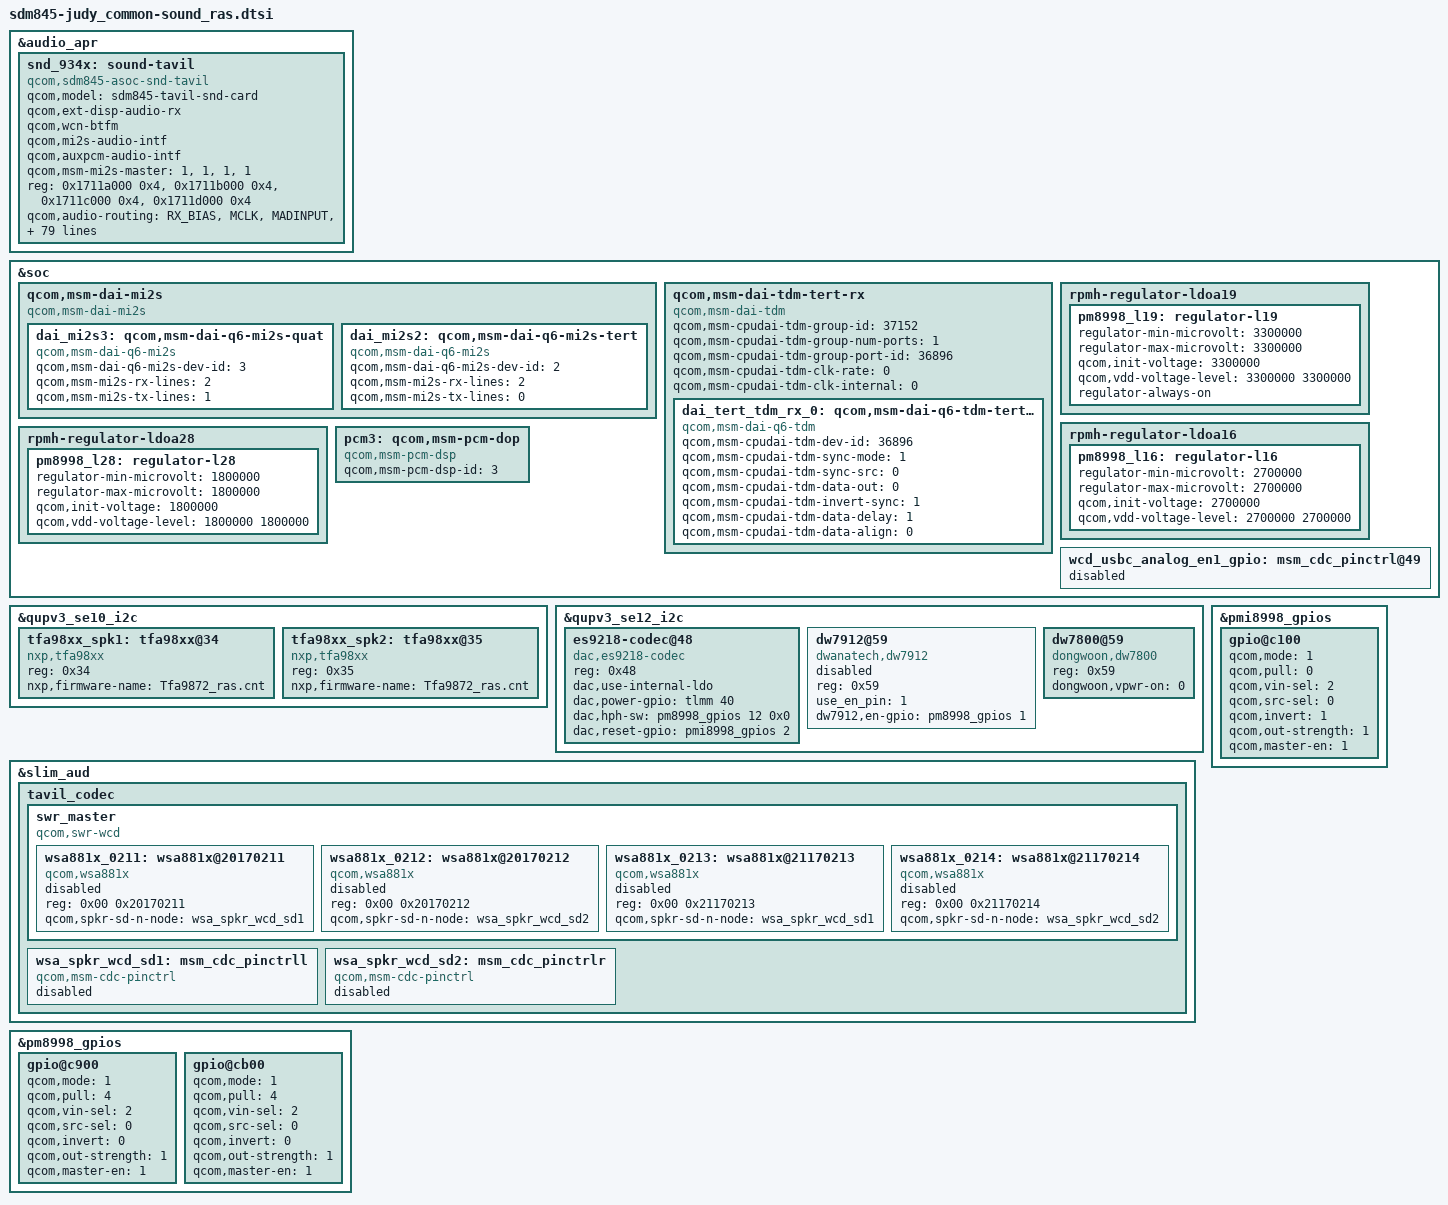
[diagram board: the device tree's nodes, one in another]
/* Copyright (c) 2017, The Linux Foundation. All rights reserved.
 *
 * This program is free software; you can redistribute it and/or modify
 * it under the terms of the GNU General Public License version 2 and
 * only version 2 as published by the Free Software Foundation.
 *
 * This program is distributed in the hope that it will be useful,
 * but WITHOUT ANY WARRANTY; without even the implied warranty of
 * MERCHANTABILITY or FITNESS FOR A PARTICULAR PURPOSE.  See the
 * GNU General Public License for more details.
 */

#include "sdm845-judy_common-sound_overlay.dtsi"
/*
&qupv3_se12_i2c {
	status = "ok";
};
*/
&audio_apr {
	snd_934x: sound-tavil {
		compatible = "qcom,sdm845-asoc-snd-tavil";
		qcom,model = "sdm845-tavil-snd-card";
		qcom,ext-disp-audio-rx;
		qcom,wcn-btfm;
		qcom,mi2s-audio-intf;
		qcom,auxpcm-audio-intf;
		qcom,msm-mi2s-master = <1>, <1>, <1>, <1>;

		reg = <0x1711a000 0x4>,
		      <0x1711b000 0x4>,
		      <0x1711c000 0x4>,
		      <0x1711d000 0x4>;
		reg-names = "lpaif_pri_mode_muxsel",
			    "lpaif_sec_mode_muxsel",
			    "lpaif_tert_mode_muxsel",
			    "lpaif_quat_mode_muxsel";

		qcom,audio-routing =
			"RX_BIAS", "MCLK",
			"MADINPUT", "MCLK",
			"AMIC1", "MIC BIAS1",
			"MIC BIAS1", "Handset Mic",
			"AMIC2", "MIC BIAS2",
			"MIC BIAS2", "Headset Mic",
			"AMIC3", "MIC BIAS3",
			"MIC BIAS3", "Handset 2nd Mic",
			"AMIC4", "MIC BIAS4",
			"MIC BIAS4", "Handset 3rd Mic",
			"DMIC0", "MIC BIAS1",
			"MIC BIAS1", "Digital Mic0";

		qcom,msm-mbhc-hphl-swh = <1>;
		qcom,msm-mbhc-gnd-swh = <0>;
		qcom,msm-mbhc-moist-cfg = <0>, <0>, <1>;
		/delete-property/ qcom,us-euro-gpios;
		qcom,tavil-mclk-clk-freq = <9600000>;
		asoc-platform = <&pcm0>, <&pcm1>, <&pcm2>, <&pcm3>,<&voip>, <&voice>,
				<&loopback>, <&compress>, <&hostless>,
				<&afe>, <&lsm>, <&routing>, <&compr>,
				<&pcm_noirq>;
		asoc-platform-names = "msm-pcm-dsp.0", "msm-pcm-dsp.1",
				"msm-pcm-dsp.2","msm-pcm-dsp.3","msm-voip-dsp",
				"msm-pcm-voice", "msm-pcm-loopback",
				"msm-compress-dsp", "msm-pcm-hostless",
				"msm-pcm-afe", "msm-lsm-client",
				"msm-pcm-routing", "msm-compr-dsp",
				"msm-pcm-dsp-noirq";
		asoc-cpu = <&dai_hdmi>, <&dai_dp>,
				<&dai_mi2s0>, <&dai_mi2s1>,
				<&dai_mi2s2>, <&dai_mi2s3>,
				<&dai_pri_auxpcm>, <&dai_sec_auxpcm>,
				<&dai_tert_auxpcm>, <&dai_quat_auxpcm>,
				<&sb_0_rx>, <&sb_0_tx>, <&sb_1_rx>, <&sb_1_tx>,
				<&sb_2_rx>, <&sb_2_tx>, <&sb_3_rx>, <&sb_3_tx>,
				<&sb_4_rx>, <&sb_4_tx>, <&sb_5_tx>,
				<&afe_pcm_rx>, <&afe_pcm_tx>, <&afe_proxy_rx>,
				<&afe_proxy_tx>, <&incall_record_rx>,
				<&incall_record_tx>, <&incall_music_rx>,
				<&incall_music_2_rx>, <&sb_5_rx>, <&sb_6_rx>,
				<&sb_7_rx>, <&sb_7_tx>, <&sb_8_tx>,
				<&usb_audio_rx>, <&usb_audio_tx>,
				<&dai_pri_tdm_rx_0>, <&dai_pri_tdm_tx_0>,
				<&dai_sec_tdm_rx_0>, <&dai_sec_tdm_tx_0>,
				<&dai_tert_tdm_rx_0>, <&dai_tert_tdm_tx_0>,
				<&dai_quat_tdm_rx_0>, <&dai_quat_tdm_tx_0>;
		asoc-cpu-names = "msm-dai-q6-hdmi.8",  "msm-dai-q6-dp.24608",
				"msm-dai-q6-mi2s.0", "msm-dai-q6-mi2s.1",
				"msm-dai-q6-mi2s.2", "msm-dai-q6-mi2s.3",
				"msm-dai-q6-auxpcm.1", "msm-dai-q6-auxpcm.2",
				"msm-dai-q6-auxpcm.3", "msm-dai-q6-auxpcm.4",
				"msm-dai-q6-dev.16384", "msm-dai-q6-dev.16385",
				"msm-dai-q6-dev.16386", "msm-dai-q6-dev.16387",
				"msm-dai-q6-dev.16388", "msm-dai-q6-dev.16389",
				"msm-dai-q6-dev.16390", "msm-dai-q6-dev.16391",
				"msm-dai-q6-dev.16392", "msm-dai-q6-dev.16393",
				"msm-dai-q6-dev.16395", "msm-dai-q6-dev.224",
				"msm-dai-q6-dev.225", "msm-dai-q6-dev.241",
				"msm-dai-q6-dev.240", "msm-dai-q6-dev.32771",
				"msm-dai-q6-dev.32772", "msm-dai-q6-dev.32773",
				"msm-dai-q6-dev.32770", "msm-dai-q6-dev.16394",
				"msm-dai-q6-dev.16396", "msm-dai-q6-dev.16398",
				"msm-dai-q6-dev.16399", "msm-dai-q6-dev.16401",
				"msm-dai-q6-dev.28672", "msm-dai-q6-dev.28673",
				"msm-dai-q6-tdm.36864", "msm-dai-q6-tdm.36865",
				"msm-dai-q6-tdm.36880", "msm-dai-q6-tdm.36881",
				"msm-dai-q6-tdm.36896", "msm-dai-q6-tdm.36897",
				"msm-dai-q6-tdm.36912", "msm-dai-q6-tdm.36913";
		pinctrl-names = "tert-mi2s-sleep", "tert-mi2s-active","tert-tdm-sleep", "tert-tdm-active", "quat-mi2s-sleep", "quat-mi2s-active";
		pinctrl-0 = <&tert_mi2s_sleep &tert_mi2s_sd1_sleep>;
		pinctrl-1 = <&tert_mi2s_active &tert_mi2s_sd1_active>;
		pinctrl-2 = <&tert_tdm_sleep &tert_tdm_dout_sleep>;
		pinctrl-3 = <&tert_tdm_active &tert_tdm_dout_active>;
		pinctrl-4 = <&quat_mi2s_sleep &quat_mi2s_sd0_sleep &quat_mi2s_sd1_sleep>;
		pinctrl-5 = <&quat_mi2s_active &quat_mi2s_sd0_active &quat_mi2s_sd1_active>;
		asoc-codec = <&stub_codec>,  <&ext_disp_audio_codec>, <&tfa98xx_spk1>, <&tfa98xx_spk2>;
		asoc-codec-names = "msm-stub-codec.1",
				"msm-ext-disp-audio-codec-rx",
				"tfa98xx-codec.0-0034",
				"tfa98xx-codec.0-0035";
		lge,3rd-spk-amp = <1>;
		lge,ras-spk-amp = <1>;
		lge,fmradio-lna-enable-gpio = <&tlmm 128 0x00>;
		lna-supply = <&pm8998_l16>;
	};
};

&soc {
	qcom,msm-dai-mi2s {
		compatible = "qcom,msm-dai-mi2s";
		dai_mi2s3: qcom,msm-dai-q6-mi2s-quat {
                        compatible = "qcom,msm-dai-q6-mi2s";
                        qcom,msm-dai-q6-mi2s-dev-id = <3>;
                        qcom,msm-mi2s-rx-lines = <2>; /* SD1 used as output */
                        qcom,msm-mi2s-tx-lines = <1>; /* SD0 used as input */
		};

		dai_mi2s2: qcom,msm-dai-q6-mi2s-tert {
                       compatible = "qcom,msm-dai-q6-mi2s";
                       qcom,msm-dai-q6-mi2s-dev-id = <2>;
                       qcom,msm-mi2s-rx-lines = <2>; /* SD1 used as output */
                       qcom,msm-mi2s-tx-lines = <0>; /* SD0 used as input */
		};
	};

	qcom,msm-dai-tdm-tert-rx {
		compatible = "qcom,msm-dai-tdm";
		qcom,msm-cpudai-tdm-group-id = <37152>;
		qcom,msm-cpudai-tdm-group-num-ports = <1>;
		qcom,msm-cpudai-tdm-group-port-id = <36896>;
		qcom,msm-cpudai-tdm-clk-rate = <0>; // external clk
		qcom,msm-cpudai-tdm-clk-internal = <0>; /* EBIT */
		dai_tert_tdm_rx_0: qcom,msm-dai-q6-tdm-tert-rx-0 {
			compatible = "qcom,msm-dai-q6-tdm";
			qcom,msm-cpudai-tdm-dev-id = <36896>;
			qcom,msm-cpudai-tdm-sync-mode = <1>; /* long sync mode */
			qcom,msm-cpudai-tdm-sync-src = <0>; /* external source */
			qcom,msm-cpudai-tdm-data-out = <0>;
			qcom,msm-cpudai-tdm-invert-sync = <1>;
			qcom,msm-cpudai-tdm-data-delay = <1>;
			qcom,msm-cpudai-tdm-data-align = <0>;
		};
	};

//Comparator for 2Vrms Hi-Fi
//Enable LDO19A Regulator if ESS Chip is installed
	 rpmh-regulator-ldoa19 {
		status = "ok";
		pm8998_l19: regulator-l19 {
				regulator-min-microvolt = <3300000>;
				regulator-max-microvolt = <3300000>;
				qcom,init-voltage = <3300000>;
				qcom,vdd-voltage-level = <3300000 3300000>;
				regulator-always-on;
				status = "okay";
			};
	};

	rpmh-regulator-ldoa16 {
		status = "ok";
		pm8998_l16: regulator-l16 {
				regulator-min-microvolt = <2700000>;
				regulator-max-microvolt = <2700000>;
				qcom,init-voltage = <2700000>;
				qcom,vdd-voltage-level = <2700000 2700000>;
				status = "okay";
			};
	};

	rpmh-regulator-ldoa28 {
		status = "ok";
		pm8998_l28: regulator-l28 {
				regulator-min-microvolt = <1800000>;
				regulator-max-microvolt = <1800000>;
				qcom,init-voltage = <1800000>;
				qcom,vdd-voltage-level = <1800000 1800000>;
				status = "okay";
			};
	};

	wcd_usbc_analog_en1_gpio: msm_cdc_pinctrl@49 {
		status = "disabled";
	};

	pcm3: qcom,msm-pcm-dop {
		compatible = "qcom,msm-pcm-dsp";
		qcom,msm-pcm-dsp-id = <3>;
	};
};

&qupv3_se10_i2c{ /* QUPV3 SE10  */
		tfa98xx_spk1: tfa98xx@34 {
			compatible = "nxp,tfa98xx";
			status = "ok";
			reg = <0x34>;
			nxp,firmware-name = "Tfa9872_ras.cnt";
		};
		/* stereo case */
		tfa98xx_spk2: tfa98xx@35 {
			compatible = "nxp,tfa98xx";
			status = "ok";
			reg = <0x35>;
			nxp,firmware-name = "Tfa9872_ras.cnt";
		};
};

&qupv3_se12_i2c { /*QUPV3 SE12 */
		status = "ok";
		es9218-codec@48{
			compatible = "dac,es9218-codec";
			status = "ok";
			reg = <0x48>;
			dac,use-internal-ldo;
			dac,power-gpio = <&tlmm 40 0x0>;
			dac,hph-sw = <&pm8998_gpios 12 0x0>;
			dac,reset-gpio = <&pmi8998_gpios 2 0x0>;
		};
		dw7912@59 {
			compatible = "dwanatech,dw7912";
			status = "disabled";
			reg = <0x59>;
			use_en_pin = <1>; /* 1 = use en pin, 0 = do not use en pin */
			dw7912,en-gpio = <&pm8998_gpios 1 0x0>; /* gpx0_0, set to output(0x1) */
		};
		dw7800@59 {
			compatible = "dongwoon,dw7800";
			status = "ok";
			reg = <0x59>;
			dongwoon,vpwr-on = <0>;
		};
};

&slim_aud {
	/delete-node/ swr_master;

	tavil_codec {

		swr_master {
			compatible = "qcom,swr-wcd";
			#address-cells = <2>;
			#size-cells = <0>;
			wsa881x_0211: wsa881x@20170211 {
				status = "disabled";
				compatible = "qcom,wsa881x";
				reg = <0x00 0x20170211>;
				qcom,spkr-sd-n-node = <&wsa_spkr_wcd_sd1>;
			};

			wsa881x_0212: wsa881x@20170212 {
				status = "disabled";
				compatible = "qcom,wsa881x";
				reg = <0x00 0x20170212>;
				qcom,spkr-sd-n-node = <&wsa_spkr_wcd_sd2>;
			};

			wsa881x_0213: wsa881x@21170213 {
				status = "disabled";
				compatible = "qcom,wsa881x";
				reg = <0x00 0x21170213>;
				qcom,spkr-sd-n-node = <&wsa_spkr_wcd_sd1>;
			};

			wsa881x_0214: wsa881x@21170214 {
				status = "disabled";
				compatible = "qcom,wsa881x";
				reg = <0x00 0x21170214>;
				qcom,spkr-sd-n-node = <&wsa_spkr_wcd_sd2>;
			};
		};

		wsa_spkr_wcd_sd1: msm_cdc_pinctrll {
			status = "disabled";
			compatible = "qcom,msm-cdc-pinctrl";
			pinctrl-names = "aud_active", "aud_sleep";
//			pinctrl-0 = <&spkr_1_wcd_en_active>;
//			pinctrl-1 = <&spkr_1_wcd_en_sleep>;
		};

		wsa_spkr_wcd_sd2: msm_cdc_pinctrlr {
			status = "disabled";
			compatible = "qcom,msm-cdc-pinctrl";
			pinctrl-names = "aud_active", "aud_sleep";
//			pinctrl-0 = <&spkr_2_wcd_en_active>;
//			pinctrl-1 = <&spkr_2_wcd_en_sleep>;
		};
	};
};

&pm8998_gpios {
	gpio@c900 { /* GPIO 10 - HIFI_LDO_SW */
		qcom,mode = <1>;			/* Digital output */
		qcom,pull = <4>;			/* Pull down */
		qcom,vin-sel = <2>;			/* Vin2 */
		qcom,src-sel = <0>;			/* Constant */
		qcom,invert = <0>;			/* Disable Invert */
		qcom,out-strength = <1>;	/* Low */
		qcom,master-en = <1>;		/* Disable GPIO */
		status = "okay";
	};

	gpio@cb00 { /* GPIO 12 - HIFI_MODE2 */
		qcom,mode = <1>;			/* Digital output */
		qcom,pull = <4>;			/* Pull down */
		qcom,vin-sel = <2>;			/* Vin 2 */
		qcom,src-sel = <0>;			/* Constant */
		qcom,invert = <0>;			/* Invert */
		qcom,out-strength = <1>;	/* Low */
		qcom,master-en = <1>;		/* Enable GPIO */
		status = "okay";
	};
};

&pmi8998_gpios {
	gpio@c100 { /* GPIO 2 - HIFI_RESET_N */
		qcom,mode = <1>;			/* Digital output*/
		qcom,pull = <0>;			/* Pull down 30uA */
		qcom,vin-sel = <2>;			/* VIN2 */
		qcom,src-sel = <0>;			/* Constant */
		qcom,invert = <1>;			/* Enable Invert */
		qcom,out-strength = <1>;	/* Low */
		qcom,master-en = <1>;		/* Enable GPIO */
		status = "okay";
	};
};

